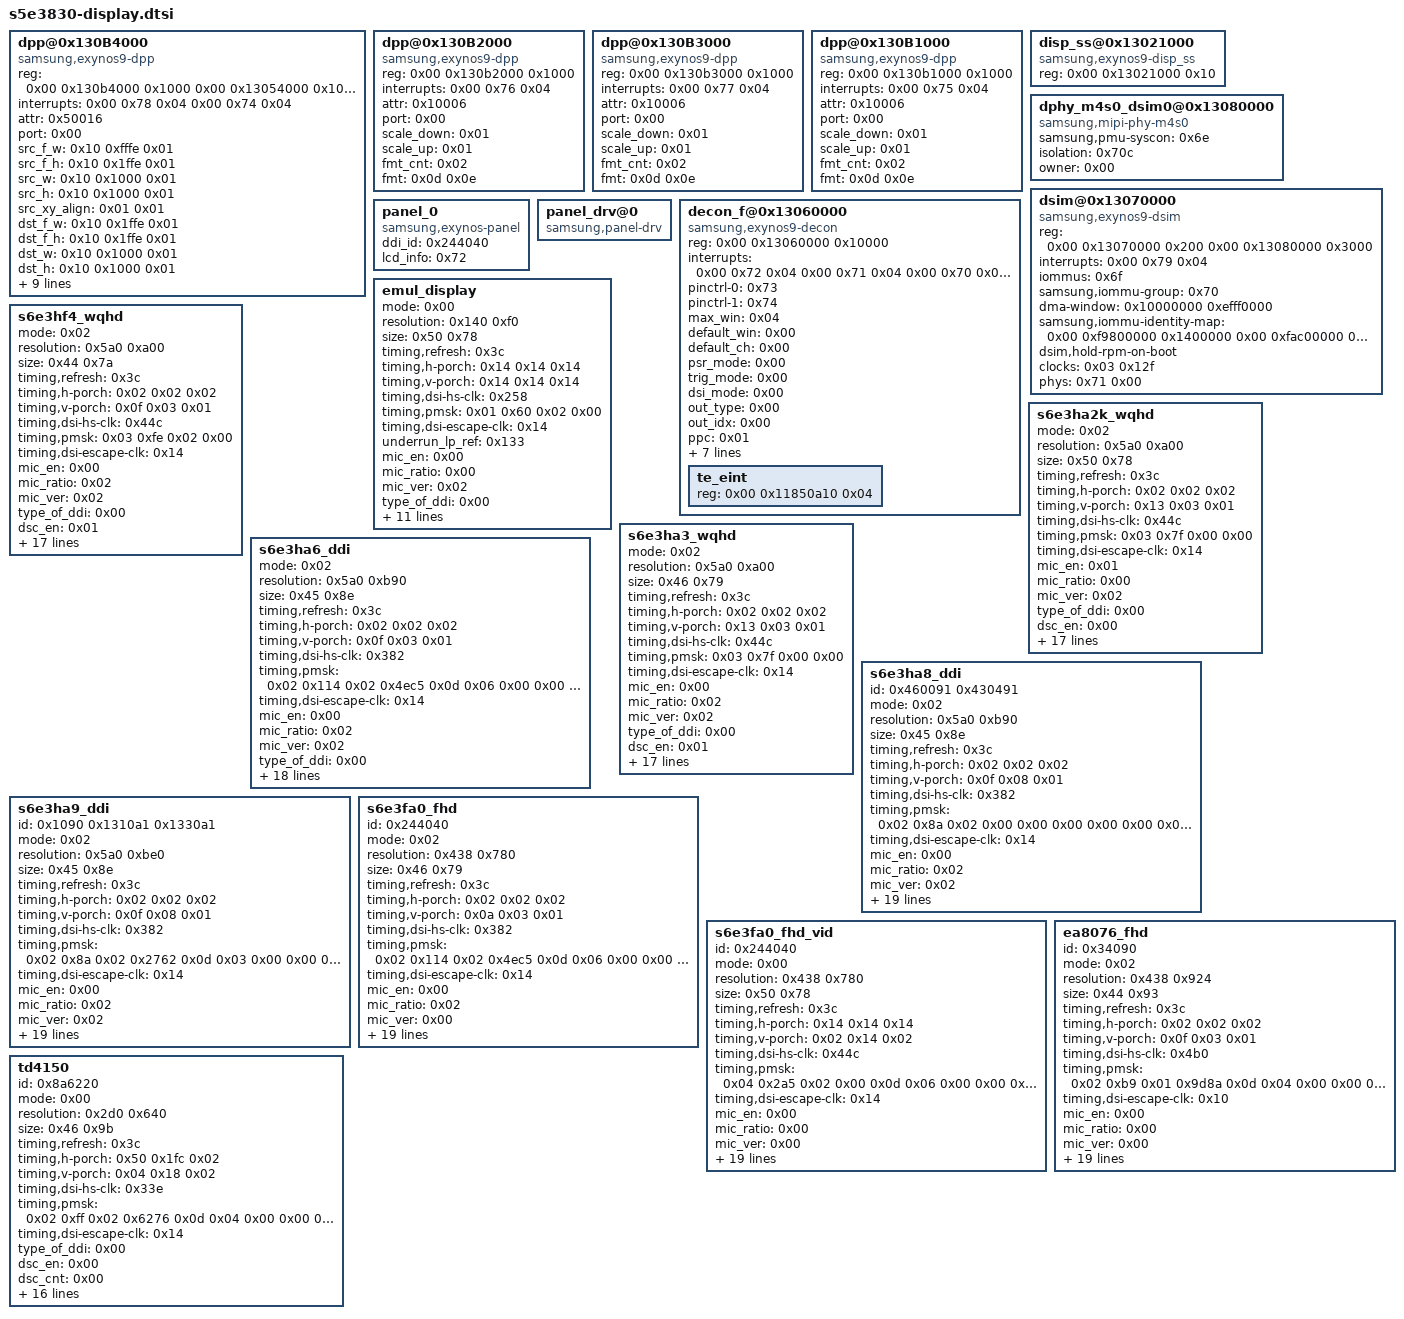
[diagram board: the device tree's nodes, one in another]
/* Samsung Exynos 850 (S5E3830) - DECON display pipeline and panel overlay */

	fragment@lcd {
		target-path = "/";

		__overlay__ {

			emul_display {
				mode = <0x00>;
				resolution = <0x140 0xf0>;
				size = <0x50 0x78>;
				timing,refresh = <0x3c>;
				timing,h-porch = <0x14 0x14 0x14>;
				timing,v-porch = <0x14 0x14 0x14>;
				timing,dsi-hs-clk = <0x258>;
				timing,pmsk = <0x01 0x60 0x02 0x00>;
				timing,dsi-escape-clk = <0x14>;
				underrun_lp_ref = <0x133>;
				mic_en = <0x00>;
				mic_ratio = <0x00>;
				mic_ver = <0x02>;
				type_of_ddi = <0x00>;
				dsc_en = <0x00>;
				dsc_cnt = <0x00>;
				dsc_slice_num = <0x00>;
				data_lane = <0x04>;
				cmd_underrun_lp_ref = <0x4b3>;
				vt_compensation = <0x29eb>;
				hdr_num = <0x00>;
				hdr_type = <0x00 0x00 0x00 0x00>;
				hdr_max_luma = <0x00>;
				hdr_max_avg_luma = <0x00>;
				hdr_min_luma = <0x00>;
				phandle = <0x106>;
			};

			s6e3hf4_wqhd {
				mode = <0x02>;
				resolution = <0x5a0 0xa00>;
				size = <0x44 0x7a>;
				timing,refresh = <0x3c>;
				timing,h-porch = <0x02 0x02 0x02>;
				timing,v-porch = <0x0f 0x03 0x01>;
				timing,dsi-hs-clk = <0x44c>;
				timing,pmsk = <0x03 0xfe 0x02 0x00>;
				timing,dsi-escape-clk = <0x14>;
				mic_en = <0x00>;
				mic_ratio = <0x02>;
				mic_ver = <0x02>;
				type_of_ddi = <0x00>;
				dsc_en = <0x01>;
				dsc_cnt = <0x02>;
				dsc_slice_num = <0x04>;
				dsc_slice_h = <0x40>;
				data_lane = <0x04>;
				cmd_underrun_lp_ref = <0x15fd>;
				mres_en = <0x00>;
				mres_number = <0x01>;
				mres_width = <0x5a0 0x00 0x00>;
				mres_height = <0xa00 0x00 0x00>;
				mres_dsc_width = <0x168 0x00 0x00>;
				mres_dsc_height = <0x40 0x00 0x00>;
				mres_dsc_en = <0x01 0x00 0x00>;
				hdr_num = <0x01>;
				hdr_type = <0x02 0x00 0x00 0x00>;
				hdr_max_luma = <0x5265c0>;
				hdr_max_avg_luma = <0x124f80>;
				hdr_min_luma = <0x05>;
				phandle = <0x107>;
			};

			s6e3ha2k_wqhd {
				mode = <0x02>;
				resolution = <0x5a0 0xa00>;
				size = <0x50 0x78>;
				timing,refresh = <0x3c>;
				timing,h-porch = <0x02 0x02 0x02>;
				timing,v-porch = <0x13 0x03 0x01>;
				timing,dsi-hs-clk = <0x44c>;
				timing,pmsk = <0x03 0x7f 0x00 0x00>;
				timing,dsi-escape-clk = <0x14>;
				mic_en = <0x01>;
				mic_ratio = <0x00>;
				mic_ver = <0x02>;
				type_of_ddi = <0x00>;
				dsc_en = <0x00>;
				dsc_cnt = <0x00>;
				dsc_slice_num = <0x00>;
				dsc_slice_h = <0x00>;
				data_lane = <0x04>;
				cmd_underrun_lp_ref = <0x4b3>;
				mres_en = <0x00>;
				mres_number = <0x01>;
				mres_width = <0x5a0 0x00 0x00>;
				mres_height = <0xa00 0x00 0x00>;
				mres_dsc_width = <0x00 0x00 0x00>;
				mres_dsc_height = <0x00 0x00 0x00>;
				mres_dsc_en = <0x00 0x00 0x00>;
				hdr_num = <0x01>;
				hdr_type = <0x02 0x00 0x00 0x00>;
				hdr_max_luma = <0x5265c0>;
				hdr_max_avg_luma = <0x124f80>;
				hdr_min_luma = <0x05>;
				phandle = <0x108>;
			};

			s6e3ha3_wqhd {
				mode = <0x02>;
				resolution = <0x5a0 0xa00>;
				size = <0x46 0x79>;
				timing,refresh = <0x3c>;
				timing,h-porch = <0x02 0x02 0x02>;
				timing,v-porch = <0x13 0x03 0x01>;
				timing,dsi-hs-clk = <0x44c>;
				timing,pmsk = <0x03 0x7f 0x00 0x00>;
				timing,dsi-escape-clk = <0x14>;
				mic_en = <0x00>;
				mic_ratio = <0x02>;
				mic_ver = <0x02>;
				type_of_ddi = <0x00>;
				dsc_en = <0x01>;
				dsc_cnt = <0x01>;
				dsc_slice_num = <0x01>;
				dsc_slice_h = <0x20>;
				data_lane = <0x04>;
				cmd_underrun_lp_ref = <0x4b3>;
				mres_en = <0x00>;
				mres_number = <0x01>;
				mres_width = <0x5a0 0x00 0x00>;
				mres_height = <0xa00 0x00 0x00>;
				mres_dsc_width = <0x5a0 0x00 0x00>;
				mres_dsc_height = <0x20 0x00 0x00>;
				mres_dsc_en = <0x01 0x00 0x00>;
				hdr_num = <0x01>;
				hdr_type = <0x02 0x00 0x00 0x00>;
				hdr_max_luma = <0x5265c0>;
				hdr_max_avg_luma = <0x124f80>;
				hdr_min_luma = <0x05>;
				phandle = <0x109>;
			};

			s6e3ha6_ddi {
				mode = <0x02>;
				resolution = <0x5a0 0xb90>;
				size = <0x45 0x8e>;
				timing,refresh = <0x3c>;
				timing,h-porch = <0x02 0x02 0x02>;
				timing,v-porch = <0x0f 0x03 0x01>;
				timing,dsi-hs-clk = <0x382>;
				timing,pmsk = <0x02 0x114 0x02 0x4ec5 0x0d 0x06 0x00 0x00 0x00 0x00 0x00 0x00 0x00 0x00>;
				timing,dsi-escape-clk = <0x14>;
				mic_en = <0x00>;
				mic_ratio = <0x02>;
				mic_ver = <0x02>;
				type_of_ddi = <0x00>;
				dsc_en = <0x01>;
				dsc_cnt = <0x02>;
				dsc_slice_num = <0x02>;
				dsc_slice_h = <0x28>;
				data_lane = <0x04>;
				cmd_underrun_lp_ref = <0xea0 0x14ef 0x110f>;
				mres_en = <0x01>;
				mres_number = <0x03>;
				mres_width = <0x5a0 0x438 0x2d0>;
				mres_height = <0xb90 0x8ac 0x5c8>;
				mres_dsc_width = <0x2d0 0x21c 0x168>;
				mres_dsc_height = <0x28 0x1e 0x4a>;
				mres_dsc_en = <0x01 0x01 0x00>;
				hdr_num = <0x01>;
				hdr_type = <0x02 0x00 0x00 0x00>;
				hdr_max_luma = <0x5265c0>;
				hdr_max_avg_luma = <0x124f80>;
				hdr_min_luma = <0x05>;
				phandle = <0x10a>;
			};

			s6e3ha8_ddi {
				id = <0x460091 0x430491>;
				mode = <0x02>;
				resolution = <0x5a0 0xb90>;
				size = <0x45 0x8e>;
				timing,refresh = <0x3c>;
				timing,h-porch = <0x02 0x02 0x02>;
				timing,v-porch = <0x0f 0x08 0x01>;
				timing,dsi-hs-clk = <0x382>;
				timing,pmsk = <0x02 0x8a 0x02 0x00 0x00 0x00 0x00 0x00 0x00 0x00 0x00 0x00 0x00 0x00>;
				timing,dsi-escape-clk = <0x14>;
				mic_en = <0x00>;
				mic_ratio = <0x02>;
				mic_ver = <0x02>;
				type_of_ddi = <0x00>;
				dsc_en = <0x01>;
				dsc_cnt = <0x02>;
				dsc_slice_num = <0x02>;
				dsc_slice_h = <0x28>;
				data_lane = <0x04>;
				cmd_underrun_cnt = <0xbce 0x14ef 0x1b77>;
				mres_en = <0x00>;
				mres_number = <0x03>;
				mres_width = <0x5a0 0x438 0x2d0>;
				mres_height = <0xb90 0x8ac 0x5c8>;
				mres_dsc_width = <0x2d0 0x21c 0x168>;
				mres_dsc_height = <0x28 0x1e 0x4a>;
				mres_dsc_en = <0x01 0x01 0x01>;
				hdr_num = <0x01>;
				hdr_type = <0x02 0x00 0x00 0x00>;
				hdr_max_luma = <0x5265c0>;
				hdr_max_avg_luma = <0x124f80>;
				hdr_min_luma = <0x05>;
				phandle = <0x10b>;
			};

			s6e3ha9_ddi {
				id = <0x1090 0x1310a1 0x1330a1>;
				mode = <0x02>;
				resolution = <0x5a0 0xbe0>;
				size = <0x45 0x8e>;
				timing,refresh = <0x3c>;
				timing,h-porch = <0x02 0x02 0x02>;
				timing,v-porch = <0x0f 0x08 0x01>;
				timing,dsi-hs-clk = <0x382>;
				timing,pmsk = <0x02 0x8a 0x02 0x2762 0x0d 0x03 0x00 0x00 0x00 0x00 0x00 0x00 0x00 0x00>;
				timing,dsi-escape-clk = <0x14>;
				mic_en = <0x00>;
				mic_ratio = <0x02>;
				mic_ver = <0x02>;
				type_of_ddi = <0x00>;
				dsc_en = <0x01>;
				dsc_cnt = <0x02>;
				dsc_slice_num = <0x02>;
				dsc_slice_h = <0x28>;
				data_lane = <0x04>;
				cmd_underrun_cnt = <0xb3d 0x149e 0x1b52>;
				mres_en = <0x01>;
				mres_number = <0x03>;
				mres_width = <0x5a0 0x438 0x2d0>;
				mres_height = <0xbe0 0x8e8 0x5f0>;
				mres_dsc_width = <0x2d0 0x21c 0x168>;
				mres_dsc_height = <0x28 0x1e 0x4a>;
				mres_dsc_en = <0x01 0x01 0x01>;
				hdr_num = <0x01>;
				hdr_type = <0x02 0x00 0x00 0x00>;
				hdr_max_luma = <0x5265c0>;
				hdr_max_avg_luma = <0x124f80>;
				hdr_min_luma = <0x05>;
				phandle = <0x10c>;
			};

			s6e3fa0_fhd {
				id = <0x244040>;
				mode = <0x02>;
				resolution = <0x438 0x780>;
				size = <0x46 0x79>;
				timing,refresh = <0x3c>;
				timing,h-porch = <0x02 0x02 0x02>;
				timing,v-porch = <0x0a 0x03 0x01>;
				timing,dsi-hs-clk = <0x382>;
				timing,pmsk = <0x02 0x114 0x02 0x4ec5 0x0d 0x06 0x00 0x00 0x00 0x00 0x00 0x00 0x00 0x00>;
				timing,dsi-escape-clk = <0x14>;
				mic_en = <0x00>;
				mic_ratio = <0x02>;
				mic_ver = <0x00>;
				type_of_ddi = <0x00>;
				dsc_en = <0x00>;
				dsc_cnt = <0x00>;
				dsc_slice_num = <0x00>;
				dsc_slice_h = <0x28>;
				data_lane = <0x04>;
				cmd_underrun_cnt = <0x247>;
				mres_en = <0x00>;
				mres_number = <0x03>;
				mres_width = <0x5a0 0x438 0x2d0>;
				mres_height = <0xb90 0x8ac 0x5c8>;
				mres_dsc_width = <0x2d0 0x21c 0x168>;
				mres_dsc_height = <0x28 0x1e 0x4a>;
				mres_dsc_en = <0x01 0x01 0x00>;
				hdr_num = <0x01>;
				hdr_type = <0x02 0x00 0x00 0x00>;
				hdr_max_luma = <0x5265c0>;
				hdr_max_avg_luma = <0x124f80>;
				hdr_min_luma = <0x05>;
				phandle = <0x72>;
			};

			s6e3fa0_fhd_vid {
				id = <0x244040>;
				mode = <0x00>;
				resolution = <0x438 0x780>;
				size = <0x50 0x78>;
				timing,refresh = <0x3c>;
				timing,h-porch = <0x14 0x14 0x14>;
				timing,v-porch = <0x02 0x14 0x02>;
				timing,dsi-hs-clk = <0x44c>;
				timing,pmsk = <0x04 0x2a5 0x02 0x00 0x0d 0x06 0x00 0x00 0x00 0x00 0x00 0x00 0x00 0x00>;
				timing,dsi-escape-clk = <0x14>;
				mic_en = <0x00>;
				mic_ratio = <0x00>;
				mic_ver = <0x00>;
				type_of_ddi = <0x00>;
				dsc_en = <0x00>;
				dsc_cnt = <0x00>;
				dsc_slice_num = <0x00>;
				data_lane = <0x04>;
				cmd_underrun_cnt = <0x134e>;
				vt_compensation = <0x27>;
				mres_en = <0x00>;
				mres_number = <0x03>;
				mres_width = <0x5a0 0x438 0x2d0>;
				mres_height = <0xb90 0x8ac 0x5c8>;
				mres_dsc_width = <0x2d0 0x21c 0x168>;
				mres_dsc_height = <0x28 0x1e 0x4a>;
				mres_dsc_en = <0x01 0x01 0x00>;
				hdr_num = <0x01>;
				hdr_type = <0x02 0x00 0x00 0x00>;
				hdr_max_luma = <0x5265c0>;
				hdr_max_avg_luma = <0x124f80>;
				hdr_min_luma = <0x05>;
				phandle = <0x10d>;
			};

			ea8076_fhd {
				id = <0x34090>;
				mode = <0x02>;
				resolution = <0x438 0x924>;
				size = <0x44 0x93>;
				timing,refresh = <0x3c>;
				timing,h-porch = <0x02 0x02 0x02>;
				timing,v-porch = <0x0f 0x03 0x01>;
				timing,dsi-hs-clk = <0x4b0>;
				timing,pmsk = <0x02 0xb9 0x01 0x9d8a 0x0d 0x04 0x00 0x00 0x00 0x00 0x00 0x00 0x00 0x00>;
				timing,dsi-escape-clk = <0x10>;
				mic_en = <0x00>;
				mic_ratio = <0x00>;
				mic_ver = <0x00>;
				type_of_ddi = <0x01>;
				dsc_en = <0x00>;
				dsc_cnt = <0x00>;
				dsc_slice_num = <0x00>;
				dsc_slice_h = <0x28>;
				data_lane = <0x04>;
				cmd_underrun_cnt = <0x69f>;
				mres_en = <0x00>;
				mres_number = <0x03>;
				mres_width = <0x5a0 0x438 0x2d0>;
				mres_height = <0xb90 0x8ac 0x5c8>;
				mres_dsc_width = <0x2d0 0x21c 0x168>;
				mres_dsc_height = <0x28 0x1e 0x4a>;
				mres_dsc_en = <0x01 0x01 0x00>;
				hdr_num = <0x01>;
				hdr_type = <0x02 0x00 0x00 0x00>;
				hdr_max_luma = <0x5265c0>;
				hdr_max_avg_luma = <0x124f80>;
				hdr_min_luma = <0x05>;
				phandle = <0x10e>;
			};

			td4150 {
				id = <0x8a6220>;
				mode = <0x00>;
				resolution = <0x2d0 0x640>;
				size = <0x46 0x9b>;
				timing,refresh = <0x3c>;
				timing,h-porch = <0x50 0x1fc 0x02>;
				timing,v-porch = <0x04 0x18 0x02>;
				timing,dsi-hs-clk = <0x33e>;
				timing,pmsk = <0x02 0xff 0x02 0x6276 0x0d 0x04 0x00 0x00 0x00 0x00 0x00 0x00 0x00 0x00>;
				timing,dsi-escape-clk = <0x14>;
				type_of_ddi = <0x00>;
				dsc_en = <0x00>;
				dsc_cnt = <0x00>;
				dsc_slice_num = <0x00>;
				dsc_slice_h = <0x00>;
				data_lane = <0x04>;
				mres_en = <0x00>;
				mres_number = <0x01>;
				mres_width = <0x438>;
				mres_height = <0x924>;
				mres_dsc_width = <0x00>;
				mres_dsc_height = <0x00>;
				mres_dsc_en = <0x00>;
				hdr_num = <0x00>;
				hdr_type = <0x02 0x00 0x00 0x00>;
				hdr_max_luma = <0x5265c0>;
				hdr_max_avg_luma = <0x124f80>;
				hdr_min_luma = <0x05>;
				underrun_max_num = <0x05>;
				phandle = <0x10f>;
			};
		};
	};

	dpp@0x130B4000 {
		compatible = "samsung,exynos9-dpp";
		#pb-id-cells = <0x03>;
		reg = <0x00 0x130b4000 0x1000 0x00 0x13054000 0x1000 0x00 0x130b0000 0x110>;
		interrupts = <0x00 0x78 0x04 0x00 0x74 0x04>;
		attr = <0x50016>;
		port = <0x00>;
		src_f_w = <0x10 0xfffe 0x01>;
		src_f_h = <0x10 0x1ffe 0x01>;
		src_w = <0x10 0x1000 0x01>;
		src_h = <0x10 0x1000 0x01>;
		src_xy_align = <0x01 0x01>;
		dst_f_w = <0x10 0x1ffe 0x01>;
		dst_f_h = <0x10 0x1ffe 0x01>;
		dst_w = <0x10 0x1000 0x01>;
		dst_h = <0x10 0x1000 0x01>;
		dst_xy_align = <0x01 0x01>;
		blk_w = <0x04 0x1000 0x01>;
		blk_h = <0x01 0x1000 0x01>;
		blk_xy_align = <0x01 0x01>;
		src_h_rot_max = <0x870>;
		scale_down = <0x01>;
		scale_up = <0x01>;
		fmt_cnt = <0x07>;
		fmt = <0x0d 0x0e 0x16 0x17 0x18 0x19 0x1e>;
		phandle = <0x110>;
	};

	dpp@0x130B2000 {
		compatible = "samsung,exynos9-dpp";
		#pb-id-cells = <0x03>;
		reg = <0x00 0x130b2000 0x1000>;
		interrupts = <0x00 0x76 0x04>;
		attr = <0x10006>;
		port = <0x00>;
		scale_down = <0x01>;
		scale_up = <0x01>;
		fmt_cnt = <0x02>;
		fmt = <0x0d 0x0e>;
		phandle = <0x111>;
	};

	dpp@0x130B3000 {
		compatible = "samsung,exynos9-dpp";
		#pb-id-cells = <0x03>;
		reg = <0x00 0x130b3000 0x1000>;
		interrupts = <0x00 0x77 0x04>;
		attr = <0x10006>;
		port = <0x00>;
		scale_down = <0x01>;
		scale_up = <0x01>;
		fmt_cnt = <0x02>;
		fmt = <0x0d 0x0e>;
		phandle = <0x112>;
	};

	dpp@0x130B1000 {
		compatible = "samsung,exynos9-dpp";
		#pb-id-cells = <0x03>;
		reg = <0x00 0x130b1000 0x1000>;
		interrupts = <0x00 0x75 0x04>;
		attr = <0x10006>;
		port = <0x00>;
		scale_down = <0x01>;
		scale_up = <0x01>;
		fmt_cnt = <0x02>;
		fmt = <0x0d 0x0e>;
		phandle = <0x113>;
	};

	disp_ss@0x13021000 {
		compatible = "samsung,exynos9-disp_ss";
		reg = <0x00 0x13021000 0x10>;
		phandle = <0x114>;
	};

	dphy_m4s0_dsim0@0x13080000 {
		compatible = "samsung,mipi-phy-m4s0";
		samsung,pmu-syscon = <0x6e>;
		isolation = <0x70c>;
		owner = <0x00>;
		#phy-cells = <0x01>;
		phandle = <0x71>;
	};

	dsim@0x13070000 {
		compatible = "samsung,exynos9-dsim";
		reg = <0x00 0x13070000 0x200 0x00 0x13080000 0x3000>;
		interrupts = <0x00 0x79 0x04>;
		iommus = <0x6f>;
		samsung,iommu-group = <0x70>;
		#dma-address-cells = <0x01>;
		#dma-size-cells = <0x01>;
		ranges;
		dma-window = <0x10000000 0xefff0000>;
		samsung,iommu-identity-map = <0x00 0xf9800000 0x1400000 0x00 0xfac00000 0x1400000>;
		dsim,hold-rpm-on-boot;
		clock-names = "aclk";
		clocks = <0x03 0x12f>;
		phys = <0x71 0x00>;
		phy-names = "dsim_dphy";
		phandle = <0x115>;
	};

	panel_0 {
		compatible = "samsung,exynos-panel";
		ddi_id = <0x244040>;
		lcd_info = <0x72>;
		phandle = <0x116>;
	};

	panel_drv@0 {
		compatible = "samsung,panel-drv";
		phandle = <0x117>;
	};

	decon_f@0x13060000 {
		compatible = "samsung,exynos9-decon";
		#pb-id-cells = <0x04>;
		reg = <0x00 0x13060000 0x10000>;
		interrupts = <0x00 0x72 0x04 0x00 0x71 0x04 0x00 0x70 0x04 0x00 0x22 0x04>;
		pinctrl-names = "hw_te_on\0hw_te_off";
		pinctrl-0 = <0x73>;
		pinctrl-1 = <0x74>;
		max_win = <0x04>;
		default_win = <0x00>;
		default_ch = <0x00>;
		psr_mode = <0x00>;
		trig_mode = <0x00>;
		dsi_mode = <0x00>;
		out_type = <0x00>;
		out_idx = <0x00>;
		ppc = <0x01>;
		line_mem_cnt = <0x04>;
		cycle_per_line = <0x08>;
		chip_ver = <0xef6>;
		dpp_cnt = <0x04>;
		dsim_cnt = <0x01>;
		decon_cnt = <0x01>;
		#address-cells = <0x02>;
		#size-cells = <0x01>;
		ranges;
		gpios = <0x1d 0x01 0x0f>;
		phandle = <0x118>;

		te_eint {
			reg = <0x00 0x11850a10 0x04>;
		};
	};
